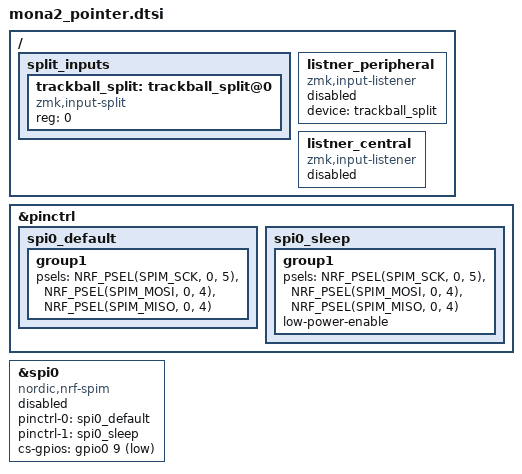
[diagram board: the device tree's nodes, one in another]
#include <zephyr/dt-bindings/input/input-event-codes.h>
#include <input/processors.dtsi>

/ {
    // dongle listner
    split_inputs {
        #address-cells = <1>;
        #size-cells = <0>;
        
        trackball_split: trackball_split@0 {
            compatible = "zmk,input-split";
            reg = <0>;
        };
    };

    listner_peripheral: listner_peripheral {
        compatible = "zmk,input-listener";
        status = "disabled";
        device = <&trackball_split>;
    };

    listner_central: listner_central {
        compatible = "zmk,input-listener";
        status = "disabled";
    };

};

&pinctrl {
    spi0_default: spi0_default {    //通常時(SPI通信中)のピン構成
        group1 {
            psels = <NRF_PSEL(SPIM_SCK, 0, 5)>, //P0.05を指定(SCLK)
                <NRF_PSEL(SPIM_MOSI, 0, 4)>,    //P0.04を指定(SDIOだからMOSI,MISO両方の役割を担う)
                <NRF_PSEL(SPIM_MISO, 0, 4)>;
        };
    };

    spi0_sleep: spi0_sleep {    //スリープ時のピン構成(省電力)
        group1 {
            psels = <NRF_PSEL(SPIM_SCK, 0, 5)>,
                <NRF_PSEL(SPIM_MOSI, 0, 4)>,
                <NRF_PSEL(SPIM_MISO, 0, 4)>;
            low-power-enable;
        };
    };
};

&spi0 {
    status = "disabled";
    compatible = "nordic,nrf-spim"; //マイコンがnRFシリーズ
    pinctrl-0 = <&spi0_default>;
    pinctrl-1 = <&spi0_sleep>;
    pinctrl-names = "default", "sleep";
    cs-gpios = <&gpio0 9 GPIO_ACTIVE_LOW>;  //P0.09を指定(CS)
};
